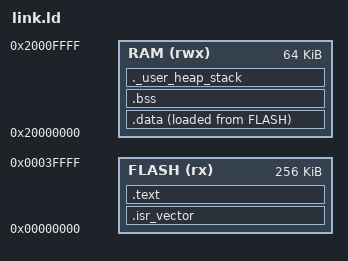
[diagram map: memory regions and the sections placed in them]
ENTRY(Reset_Handler)

MEMORY
{
    FLASH (rx)  : ORIGIN = 0x00000000, LENGTH = 256K
    RAM   (rwx) : ORIGIN = 0x20000000, LENGTH = 64K
}

_estack = ORIGIN(RAM) + LENGTH(RAM);

SECTIONS
{
    .isr_vector :
    {
        . = ALIGN(4);
        KEEP(*(.isr_vector))
        . = ALIGN(4);
    } > FLASH

    .text :
    {
        . = ALIGN(4);
        *(.text*)
        *(.rodata*)
        . = ALIGN(4);
        _etext = .;
    } > FLASH

    .data : 
    {
        . = ALIGN(4);
        _sdata = .;
        *(.data*)
        . = ALIGN(4);
        _edata = .;
    } > RAM AT> FLASH

    _sidata = LOADADDR(.data);

    .bss :
    {
        . = ALIGN(4);
        _sbss = .;
        *(.bss*)
        *(COMMON)
        . = ALIGN(4);
        _ebss = .;
    } > RAM

    ._user_heap_stack :
    {
        . = ALIGN(8);
        . = . + 1024;
        . = ALIGN(8);
    } > RAM
}
